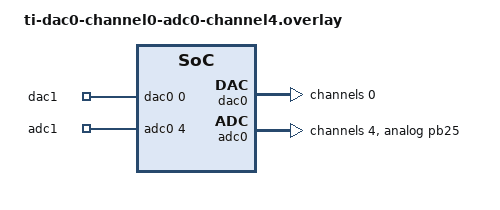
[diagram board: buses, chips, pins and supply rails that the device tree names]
/*
 * Copyright (c) 2026 Texas Instruments Incorporated
 *
 * SPDX-License-Identifier: Apache-2.0
 */

#include <dt-bindings/adc/adc.h>

/ {
	zephyr,user {
		io-channels = <&dac0 0 &adc0 4>;
		io-channel-names = "dac1", "adc1";
	};
};

&dac0 {
	#address-cells = <1>;
	#size-cells = <0>;

	channel@0 {
		reg = <0>;
		zephyr,resolution = <12>;
		zephyr,buffered;
	};
};

&adc0 {
	pinctrl-0 = <&analog_pb25>;
	pinctrl-names = "default";
	status = "okay";
	#address-cells = <1>;
	#size-cells = <0>;

	channel@4 {
		reg = <4>;
		zephyr,gain = "ADC_GAIN_1";
		zephyr,reference = "ADC_REF_VDD_1";
		zephyr,vref-mv = <3300>;
		zephyr,acquisition-time = <ADC_ACQ_TIME(ADC_ACQ_TIME_MICROSECONDS, 5)>;
		zephyr,resolution = <12>;
	};
};
